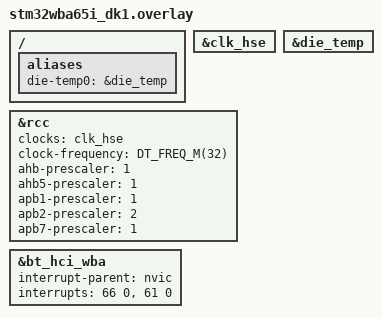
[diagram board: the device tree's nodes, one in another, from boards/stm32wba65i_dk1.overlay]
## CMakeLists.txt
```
# SPDX-License-Identifier: Apache-2.0
cmake_minimum_required(VERSION 3.20.0)

find_package(Zephyr REQUIRED HINTS $ENV{ZEPHYR_BASE})
project(bleberry LANGUAGES C)

# --- Locate the Berry interpreter (fetched by west, see west.yml) ------------

if(NOT DEFINED WEST_TOPDIR)
  get_filename_component(WEST_TOPDIR ${ZEPHYR_BASE}/.. ABSOLUTE)
endif()

set(BERRY_DIR ${WEST_TOPDIR}/modules/lib/berry CACHE PATH
    "Path to the Berry language source tree")

if(NOT EXISTS ${BERRY_DIR}/src/berry.h)
  message(FATAL_ERROR
    "Berry sources not found at ${BERRY_DIR}. Run 'west update' first, "
    "or set BERRY_DIR to a Berry checkout.")
endif()

set(BERRY_CONF_DIR ${CMAKE_CURRENT_SOURCE_DIR}/berry_conf)
set(BERRY_GENERATE_DIR ${BERRY_DIR}/generate)

file(GLOB BERRY_SOURCES ${BERRY_DIR}/src/*.c)
file(GLOB BERRY_HEADERS ${BERRY_DIR}/src/*.h)

# --- Berry pre-build code generation ("coc") ----------------------------------
# Berry solidifies its built-in classes/modules into flash. The coc tool scans
# the sources (plus our app sources, so custom const objects work too) and
# emits the constant tables into ${BERRY_DIR}/generate, where the Berry
# sources expect to find them.

add_custom_command(
  OUTPUT ${BERRY_GENERATE_DIR}/be_const_strtab.h
  COMMAND ${CMAKE_COMMAND} -E make_directory ${BERRY_GENERATE_DIR}
  COMMAND ${PYTHON_EXECUTABLE} ${BERRY_DIR}/tools/coc/coc
          -o ${BERRY_GENERATE_DIR}
          ${BERRY_DIR}/src
          ${CMAKE_CURRENT_SOURCE_DIR}/src
          -c ${BERRY_CONF_DIR}/berry_conf.h
  DEPENDS ${BERRY_SOURCES} ${BERRY_HEADERS} ${BERRY_CONF_DIR}/berry_conf.h
  COMMENT "Berry: generating precompiled objects (coc)"
)
add_custom_target(berry_coc DEPENDS ${BERRY_GENERATE_DIR}/be_const_strtab.h)

# --- Firmware git hash (regenerated on every build) ---------------------------

set(BLEBERRY_GIT_H ${CMAKE_BINARY_DIR}/bleberry_git.h)
add_custom_target(bleberry_git_hash
  COMMAND ${CMAKE_COMMAND}
          -DSOURCE_DIR=${CMAKE_CURRENT_SOURCE_DIR}
          -DOUT=${BLEBERRY_GIT_H}
          -P ${CMAKE_CURRENT_SOURCE_DIR}/cmake/git_hash.cmake
  BYPRODUCTS ${BLEBERRY_GIT_H}
  COMMENT "Updating bleberry_git.h"
)

# --- Application ---------------------------------------------------------------
# The Berry core is compiled straight into the app target: zephyr_library()
# is not available to application CMakeLists (Zephyr application mode).

target_sources(app PRIVATE
  ${BERRY_SOURCES}
  src/main.c
  src/nus_io.c
  src/berry_repl.c
  src/berry_io.c
  src/bb_runtime.c
  src/berry_port.c
  src/be_modtab.c
)
target_include_directories(app PRIVATE
  src
  ${BERRY_DIR}/src
  ${BERRY_CONF_DIR}
  ${CMAKE_BINARY_DIR}
)
add_dependencies(app berry_coc bleberry_git_hash)
```

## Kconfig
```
# SPDX-License-Identifier: Apache-2.0

menu "BLEberry - Berry REPL over BLE NUS"

config BLEBERRY_ECHO
	bool "Echo received characters back over NUS"
	help
	  Enable this when the connected terminal does not display the
	  characters it sends (raw character terminals). Most mobile NUS
	  terminal apps (nRF Toolbox, Serial Bluetooth Terminal) show sent
	  lines themselves, so the default is off.

config BLEBERRY_LINE_MAX
	int "Maximum REPL input line length"
	default 256

config BLEBERRY_RX_RINGBUF_SIZE
	int "Receive ring buffer size in bytes"
	default 1024

config BLEBERRY_TX_BUF_SIZE
	int "Transmit coalescing buffer size in bytes"
	default 244

config BLEBERRY_REPL_STACK_SIZE
	int "Stack size of the Berry REPL thread"
	default 12288
	help
	  The Berry compiler uses recursive descent parsing, so the REPL
	  thread needs a generous stack.

config BLEBERRY_TICK_MS
	int "Scheduler tick for sps.every() tasks in ms"
	default 10
	help
	  While the REPL waits for input it periodically runs due
	  BlockBerry mini-PLC tasks (sps.every). This sets the polling
	  granularity; task intervals shorter than this are not useful.

endmenu

source "Kconfig.zephyr"
```

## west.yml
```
# BLEberry west manifest
#
# Workspace layout (T2 topology, this repo is the manifest repo):
#
#   <workspace>/
#   ├── bleberry/            <- this repository
#   ├── zephyr/              <- Zephyr RTOS (main)
#   └── modules/
#       ├── hal/stm32/       <- STM32 HAL + BLE link layer
#       └── lib/berry/       <- Berry scripting language
#
# Setup:
#   west init -l bleberry
#   west update
manifest:
  remotes:
    - name: zephyrproject-rtos
      url-base: https://github.com/zephyrproject-rtos
    - name: berry-lang
      url-base: https://github.com/berry-lang

  projects:
    - name: zephyr
      remote: zephyrproject-rtos
      revision: main
      import:
        # Only pull what the STM32WBA targets actually need.
        name-allowlist:
          - cmsis
          - cmsis_6
          - hal_stm32
          - mbedtls        # PSA crypto for the Bluetooth host
          - tf-psa-crypto  # PSA crypto core used by mbedtls 4.x

    - name: berry
      remote: berry-lang
      revision: master
      path: modules/lib/berry

  self:
    path: bleberry
```

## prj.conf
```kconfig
# Bluetooth LE peripheral with Nordic UART Service
CONFIG_BT=y
CONFIG_BT_PERIPHERAL=y
CONFIG_BT_ZEPHYR_NUS=y
CONFIG_BT_DEVICE_NAME="BLEberry"

# Larger ATT MTU / data length for a snappier REPL (peer must request it)
CONFIG_BT_L2CAP_TX_MTU=247
CONFIG_BT_BUF_ACL_TX_SIZE=251
CONFIG_BT_BUF_ACL_RX_SIZE=251

# Berry heap: the interpreter allocates from the libc malloc arena.
# Boards with more SRAM raise this in boards/<board>.conf.
CONFIG_COMMON_LIBC_MALLOC_ARENA_SIZE=32768

# Berry prints reals via printf-family formatting
CONFIG_PICOLIBC_IO_FLOAT=y

# led() native function
CONFIG_GPIO=y

# reboot() native function
CONFIG_REBOOT=y

CONFIG_RING_BUFFER=y

# Keep the UART console for log output; the REPL itself runs over BLE
CONFIG_LOG=y
CONFIG_LOG_DEFAULT_LEVEL=3
```

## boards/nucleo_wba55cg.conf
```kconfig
# STM32WBA55CG: 128 KiB SRAM - keep a moderate Berry heap
CONFIG_COMMON_LIBC_MALLOC_ARENA_SIZE=49152

# temp(): die temperature sensor (via ADC4)
CONFIG_ADC=y
CONFIG_SENSOR=y
```

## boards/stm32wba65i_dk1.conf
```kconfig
# STM32WBA65RI: 512 KiB SRAM - plenty of room for the Berry heap
CONFIG_COMMON_LIBC_MALLOC_ARENA_SIZE=196608

# temp(): die temperature sensor (via ADC4)
CONFIG_SENSOR=y

# joy(): 5-way joystick on ADC4 channel 6 (adc-keys, input subsystem)
CONFIG_INPUT=y
```

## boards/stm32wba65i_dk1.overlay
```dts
/*
 * STM32WBA65I-DK1 on Zephyr 4.4.2: radio clock, die-temp (RF calib), IRQs.
 *
 * Board DTS defaults to HSE/2 @ 16 MHz and ahb5/2 — too slow for the BLE
 * link layer (HCI comes up, advertising is not on air). Align with upstream /
 * nucleo_wba65ri: 32 MHz SYSCLK, ahb5-prescaler = 1.
 */

/ {
	aliases {
		die-temp0 = &die_temp;
	};
};

&clk_hse {
	status = "okay";
	/delete-property/ hse-div2;
	/delete-property/ hse-trimming;
};

&rcc {
	clocks = <&clk_hse>;
	clock-frequency = <DT_FREQ_M(32)>; /* minimum for radio events */
	ahb-prescaler = <1>;
	ahb5-prescaler = <1>;
	apb1-prescaler = <1>;
	apb2-prescaler = <2>;
	apb7-prescaler = <1>;
};

&die_temp {
	status = "okay";
};

/*
 * Radio IRQ (66) + SW-low (HASH=61) so NUM_IRQS is large enough
 * (Zephyr 4.4 does not yet declare these on WBA65).
 */
&bt_hci_wba {
	interrupt-parent = <&nvic>;
	interrupts = <66 0>, <61 0>;
	interrupt-names = "radio", "radio-sw-low";
};
```

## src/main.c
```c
/* SPDX-License-Identifier: Apache-2.0
 *
 * BLEberry: Berry language REPL over the Bluetooth Nordic UART Service.
 *
 * Advertises as a connectable peripheral with the NUS UUID; once a
 * central subscribes to the TX characteristic, the Berry REPL banner
 * and prompt are sent and the terminal is live.
 */
#include <zephyr/kernel.h>
#include <zephyr/bluetooth/bluetooth.h>
#include <zephyr/bluetooth/conn.h>
#include <zephyr/bluetooth/services/nus.h>
#include <zephyr/logging/log.h>

#include "nus_io.h"

LOG_MODULE_REGISTER(bleberry, CONFIG_LOG_DEFAULT_LEVEL);

const char *bleberry_banner(void);

#define DEVICE_NAME	CONFIG_BT_DEVICE_NAME
#define DEVICE_NAME_LEN	(sizeof(DEVICE_NAME) - 1)

static const struct bt_data ad[] = {
	BT_DATA_BYTES(BT_DATA_FLAGS, (BT_LE_AD_GENERAL | BT_LE_AD_NO_BREDR)),
	BT_DATA(BT_DATA_NAME_COMPLETE, DEVICE_NAME, DEVICE_NAME_LEN),
};

static const struct bt_data sd[] = {
	BT_DATA_BYTES(BT_DATA_UUID128_ALL, BT_UUID_NUS_SRV_VAL),
};

static void adv_restart(struct k_work *work)
{
	ARG_UNUSED(work);

	int err = bt_le_adv_start(BT_LE_ADV_CONN_FAST_1,
				  ad, ARRAY_SIZE(ad), sd, ARRAY_SIZE(sd));
	if (err && err != -EALREADY) {
		LOG_ERR("Advertising restart failed (err %d)", err);
	}
}
static K_WORK_DEFINE(adv_work, adv_restart);

static void send_banner(struct k_work *work)
{
	ARG_UNUSED(work);

	nus_io_send_direct(bleberry_banner());
}
static K_WORK_DEFINE(banner_work, send_banner);

/* --- NUS callbacks ------------------------------------------------------ */

static void notif_enabled(bool enabled, void *ctx)
{
	ARG_UNUSED(ctx);

	nus_io_set_ready(enabled);
	LOG_INF("NUS notifications %s", enabled ? "enabled" : "disabled");

	if (enabled) {
		k_work_submit(&banner_work);
	}
}

static void received(struct bt_conn *conn, const void *data, uint16_t len,
		     void *ctx)
{
	ARG_UNUSED(conn);
	ARG_UNUSED(ctx);

	nus_io_rx_feed(data, len);
}

static struct bt_nus_cb nus_listener = {
	.notif_enabled = notif_enabled,
	.received = received,
};

/* --- connection callbacks ----------------------------------------------- */

static void connected(struct bt_conn *conn, uint8_t err)
{
	if (err) {
		LOG_ERR("Connection failed (err 0x%02x)", err);
		return;
	}
	nus_io_set_conn(conn);
	LOG_INF("Connected");
}

static void disconnected(struct bt_conn *conn, uint8_t reason)
{
	ARG_UNUSED(conn);

	nus_io_set_conn(NULL);
	nus_io_set_ready(false);
	LOG_INF("Disconnected (reason 0x%02x)", reason);
}

static void recycled(void)
{
	k_work_submit(&adv_work);
}

BT_CONN_CB_DEFINE(conn_callbacks) = {
	.connected = connected,
	.disconnected = disconnected,
	.recycled = recycled,
};

int main(void)
{
	int err;

	err = bt_nus_cb_register(&nus_listener, NULL);
	if (err) {
		LOG_ERR("Failed to register NUS callbacks (err %d)", err);
		return err;
	}

	err = bt_enable(NULL);
	if (err) {
		LOG_ERR("Failed to enable Bluetooth (err %d)", err);
		return err;
	}

	err = bt_le_adv_start(BT_LE_ADV_CONN_FAST_1,
			      ad, ARRAY_SIZE(ad), sd, ARRAY_SIZE(sd));
	if (err) {
		LOG_ERR("Failed to start advertising (err %d)", err);
		return err;
	}

	LOG_INF("BLEberry up, advertising as \"%s\"", DEVICE_NAME);
	return 0;
}
```

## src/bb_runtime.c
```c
/* SPDX-License-Identifier: Apache-2.0
 *
 * BlockBerry runtime: the Berry-side library that code generated by the
 * BlockBerry editor (blockberry-editor/src/berry_generator.ts) calls into:
 *
 *   sps.every(ms, fn), sps.wait(ms), sps.input(ch), sps.output(ch, v)
 *   sensor.ready(), sensor.temp()
 *   escalation.raise_if(id, cond, level, msg, cooldown)
 *   signal.set(name, state)
 *   monitor.record(metric, value, unit)
 *   log.print(msg)
 *
 * Channels are plain string parameters. Board specifics are resolved here:
 *   "LED0".."LED2"      user LEDs
 *   "SW0".."SW2"        user buttons (boards with gpio-keys)
 *   "JOY_UP" etc.       joystick (boards with adc-keys)
 *   "D0".."D15"         Arduino R3 header pins (board-specific map)
 *   "PA0".."PH15"       any GPIO by port/pin
 *
 * The cyclic tasks registered with sps.every() are driven by _bb_tick(),
 * which the REPL thread calls whenever it is idle waiting for input.
 */
#include <zephyr/kernel.h>
#include <zephyr/devicetree.h>
#include <zephyr/logging/log.h>

#include "berry.h"
#include "bb_runtime.h"

LOG_MODULE_REGISTER(bb_runtime, CONFIG_LOG_DEFAULT_LEVEL);

static const char bb_runtime_be[] =
	"import string\n"
	"_bb_tasks = []\n"
	"_bb_esc = {}\n"
	"_bb_sig = {}\n"
	"_bb_cfg = {}\n"
	"_bb_cur = nil\n"
	/* "PA5" -> ['a', 5] */
	"def _bb_pin(ch)\n"
	"  if size(ch) < 3 return nil end\n"
	"  var s = string.toupper(ch)\n"
	"  if s[0] != 'P' return nil end\n"
	"  var p = s[1]\n"
	"  if p < 'A' || p > 'H' return nil end\n"
	"  var pin = 0\n"
	"  var i = 2\n"
	"  while i < size(s)\n"
	"    var c = string.byte(s[i])\n"
	"    if c < 0x30 || c > 0x39 return nil end\n"
	"    pin = pin * 10 + (c - 0x30)\n"
	"    i += 1\n"
	"  end\n"
	"  if pin > 15 return nil end\n"
	"  return [string.tolower(p), pin]\n"
	"end\n"
	/* Arduino R3 header map (board-specific) */
	"_bb_dmap = {"
#if defined(CONFIG_BOARD_STM32WBA65I_DK1)
	"'D0':['a',11],'D1':['a',12],'D2':['e',0],'D3':['b',13],"
	"'D4':['a',3],'D5':['b',14],'D6':['b',0],'D7':['d',14],"
	"'D8':['a',10],'D9':['b',11],'D10':['b',9],'D11':['c',3],"
	"'D12':['a',9],'D13':['b',10],'D14':['b',1],'D15':['b',2]"
#endif
	"}\n"
	"def _bb_gpio(ch)\n"
	"  var pp = _bb_dmap.find(string.toupper(ch))\n"
	"  if pp == nil pp = _bb_pin(ch) end\n"
	"  return pp\n"
	"end\n"
	/* digital input by channel name */
	"def _bb_din(ch)\n"
	"  ch = str(ch)\n"
#ifdef CONFIG_INPUT
	"  if ch == 'JOY_UP' return joy() == 'up' end\n"
	"  if ch == 'JOY_DOWN' return joy() == 'down' end\n"
	"  if ch == 'JOY_LEFT' return joy() == 'left' end\n"
	"  if ch == 'JOY_RIGHT' return joy() == 'right' end\n"
	"  if ch == 'JOY_SELECT' return joy() == 'enter' end\n"
#endif
#if DT_NODE_EXISTS(DT_ALIAS(sw0))
	"  if ch == 'SW0' return button(0) != 0 end\n"
#endif
#if DT_NODE_EXISTS(DT_ALIAS(sw1))
	"  if ch == 'SW1' return button(1) != 0 end\n"
#endif
#if DT_NODE_EXISTS(DT_ALIAS(sw2))
	"  if ch == 'SW2' return button(2) != 0 end\n"
#endif
	"  var pp = _bb_gpio(ch)\n"
	"  if pp == nil raise 'value_error', 'unknown input channel: ' + ch end\n"
	"  if _bb_cfg.find(ch) == nil\n"
	"    pinmode(pp[0], pp[1], 'in_pu')\n"
	"    _bb_cfg[ch] = true\n"
	"  end\n"
	"  return dread(pp[0], pp[1]) != 0\n"
	"end\n"
	/* digital output by channel name */
	"def _bb_dout(ch, v)\n"
	"  ch = str(ch)\n"
	"  v = bool(v)\n"
#if DT_NODE_EXISTS(DT_ALIAS(led0))
	"  if ch == 'LED0' led(0, v) return end\n"
#endif
#if DT_NODE_EXISTS(DT_ALIAS(led1))
	"  if ch == 'LED1' led(1, v) return end\n"
#endif
#if DT_NODE_EXISTS(DT_ALIAS(led2))
	"  if ch == 'LED2' led(2, v) return end\n"
#endif
	"  var pp = _bb_gpio(ch)\n"
	"  if pp == nil raise 'value_error', 'unknown output channel: ' + ch end\n"
	"  if _bb_cfg.find(ch) == nil\n"
	"    pinmode(pp[0], pp[1], 'out')\n"
	"    _bb_cfg[ch] = true\n"
	"  end\n"
	"  dwrite(pp[0], pp[1], v)\n"
	"end\n"
	/* --- log --- */
	"log = module('log')\n"
	"log.print = def (msg) print('[log] ' + str(msg)) end\n"
	/* --- sps: cyclic mini PLC --- */
	"sps = module('sps')\n"
	"sps.every = def (interval, fn)\n"
	"  _bb_tasks.push({'i': int(interval), 'fn': fn, 'next': millis(), 'sleep': millis()})\n"
	"end\n"
	"sps.wait = def (ms)\n"
	"  if _bb_cur != nil\n"
	"    _bb_cur['sleep'] = millis() + int(ms)\n"
	"    raise 'bb_wait'\n"
	"  end\n"
	"end\n"
	"sps.input = def (ch) return _bb_din(ch) end\n"
	"sps.output = def (ch, v) _bb_dout(ch, v) end\n"
	"sps.clear = def () _bb_tasks = [] end\n"
	"def _bb_tick()\n"
	"  var now = millis()\n"
	"  for t: _bb_tasks\n"
	"    if now - t['next'] >= 0 && now - t['sleep'] >= 0\n"
	"      t['next'] = now + t['i']\n"
	"      _bb_cur = t\n"
	"      try\n"
	"        t['fn']()\n"
	"      except 'bb_wait'\n"
	"      except .. as e, m\n"
	"        log.print('task error: ' + str(e) + ': ' + str(m))\n"
	"      end\n"
	"      _bb_cur = nil\n"
	"    end\n"
	"  end\n"
	"end\n"
	/* --- sensor: die temperature --- */
	"sensor = module('sensor')\n"
#if defined(CONFIG_SENSOR) && DT_NODE_EXISTS(DT_ALIAS(die_temp0))
	"sensor.ready = def ()\n"
	"  try\n"
	"    temp()\n"
	"    return true\n"
	"  except ..\n"
	"    return false\n"
	"  end\n"
	"end\n"
	"sensor.temp = def () return temp() end\n"
#else
	"sensor.ready = def () return false end\n"
	"sensor.temp = def () raise 'io_error', 'no temperature sensor' end\n"
#endif
	/* --- signal: named states mapped to the user LEDs --- */
	"signal = module('signal')\n"
	"signal.set = def (name, state)\n"
	"  _bb_sig[str(name)] = str(state)\n"
	"  var g = state == 'normal'\n"
	"  var r = state == 'warning' || state == 'alarm'\n"
#if DT_NODE_EXISTS(DT_ALIAS(led0))
	"  led(0, g)\n"
#endif
#if DT_NODE_EXISTS(DT_ALIAS(led1))
	"  led(1, r)\n"
#endif
	"  if !g && !r && state != 'off'\n"
	"    log.print('signal ' + str(name) + ' -> ' + str(state))\n"
	"  end\n"
	"end\n"
	"signal.get = def (name) return _bb_sig.find(str(name)) end\n"
	/* --- monitor: measurement log --- */
	"monitor = module('monitor')\n"
	"monitor.record = def (metric, value, unit)\n"
	"  log.print(str(metric) + ' = ' + str(value) + ' ' + str(unit))\n"
	"end\n"
	/* --- escalation: stateful alarms with cooldown --- */
	"escalation = module('escalation')\n"
	"escalation.raise_if = def (id, cond, level, msg, cooldown)\n"
	"  var e = _bb_esc.find(id)\n"
	"  if e == nil\n"
	"    e = {'active': false, 'last': nil}\n"
	"    _bb_esc[id] = e\n"
	"  end\n"
	"  if !cond\n"
	"    e['active'] = false\n"
	"    return false\n"
	"  end\n"
	"  if e['active'] return false end\n"
	"  var now = millis()\n"
	"  if e['last'] != nil && now - e['last'] < int(cooldown) * 1000\n"
	"    return false\n"
	"  end\n"
	"  e['active'] = true\n"
	"  e['last'] = now\n"
	"  log.print('[' + str(level) + '] ' + str(msg))\n"
	"  return true\n"
	"end\n";

int bb_runtime_load(bvm *vm)
{
	if (be_loadbuffer(vm, "bb_runtime", bb_runtime_be,
			  sizeof(bb_runtime_be) - 1) != 0) {
		LOG_ERR("BlockBerry runtime failed to compile");
		be_dumpexcept(vm);
		return -EINVAL;
	}
	if (be_pcall(vm, 0) != 0) {
		LOG_ERR("BlockBerry runtime failed to run");
		be_dumpexcept(vm);
		be_pop(vm, 1);
		return -EINVAL;
	}
	be_pop(vm, 1);
	return 0;
}

void bb_runtime_tick(bvm *vm)
{
	static bool in_tick;

	if (vm == NULL || in_tick) {
		return;
	}
	in_tick = true;

	be_getglobal(vm, "_bb_tick");
	if (be_isfunction(vm, -1)) {
		if (be_pcall(vm, 0) != 0) {
			be_dumpexcept(vm);
		}
	}
	be_pop(vm, 1);

	in_tick = false;
}
```

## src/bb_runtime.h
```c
/* SPDX-License-Identifier: Apache-2.0 */
#ifndef BLEBERRY_BB_RUNTIME_H_
#define BLEBERRY_BB_RUNTIME_H_

#include "berry.h"

/* Load the BlockBerry runtime (sps/sensor/escalation/signal/monitor/log)
 * into the VM. Returns 0 on success. */
int bb_runtime_load(bvm *vm);

/* Run due sps.every() tasks. Called from the REPL thread while it is
 * idle waiting for input. Safe to call with NULL. */
void bb_runtime_tick(bvm *vm);

#endif /* BLEBERRY_BB_RUNTIME_H_ */
```

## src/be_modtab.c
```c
/********************************************************************
** Berry module table for BLEberry.
**
** Adapted from berry/default/be_modtab.c (see the Berry LICENSE).
** Only the modules enabled in berry_conf.h end up in the table.
********************************************************************/
#include "berry.h"

be_extern_native_module(string);
be_extern_native_module(json);
be_extern_native_module(math);
be_extern_native_module(time);
be_extern_native_module(os);
be_extern_native_module(global);
be_extern_native_module(sys);
be_extern_native_module(debug);
be_extern_native_module(gc);
be_extern_native_module(solidify);
be_extern_native_module(introspect);
be_extern_native_module(strict);
be_extern_native_module(undefined);

BERRY_LOCAL const bntvmodule_t* const be_module_table[] = {
#if BE_USE_STRING_MODULE
    &be_native_module(string),
#endif
#if BE_USE_JSON_MODULE
    &be_native_module(json),
#endif
#if BE_USE_MATH_MODULE
    &be_native_module(math),
#endif
#if BE_USE_TIME_MODULE
    &be_native_module(time),
#endif
#if BE_USE_OS_MODULE
    &be_native_module(os),
#endif
#if BE_USE_GLOBAL_MODULE
    &be_native_module(global),
#endif
#if BE_USE_SYS_MODULE
    &be_native_module(sys),
#endif
#if BE_USE_DEBUG_MODULE
    &be_native_module(debug),
#endif
#if BE_USE_GC_MODULE
    &be_native_module(gc),
#endif
#if BE_USE_SOLIDIFY_MODULE
    &be_native_module(solidify),
#endif
#if BE_USE_INTROSPECT_MODULE
    &be_native_module(introspect),
#endif
#if BE_USE_STRICT_MODULE
    &be_native_module(strict),
#endif
    &be_native_module(undefined),
    NULL /* do not remove */
};

BERRY_LOCAL bclass_array be_class_table = {
    NULL, /* do not remove */
};
```

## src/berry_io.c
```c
/* SPDX-License-Identifier: Apache-2.0
 *
 * Native Berry functions for board I/O:
 *
 *   millis()               uptime in milliseconds
 *   reboot()               cold reboot
 *   led(on) / led(i, on)   user LEDs (led0..led2 aliases)
 *   button([i])            user buttons (sw0..sw2 aliases), 1 = pressed
 *   joy()                  joystick direction (adc-keys, input subsystem)
 *   temp()                 die temperature in degrees Celsius
 *   pinmode(p, pin, mode)  configure any GPIO, p = "a".."h"
 *   dwrite(p, pin, v)      write GPIO
 *   dread(p, pin)          read GPIO
 *   help()                 list what is available on this board
 *
 * Everything is guarded by devicetree/Kconfig, so boards without a
 * given peripheral simply don't get the corresponding function.
 */
#include <zephyr/kernel.h>
#include <zephyr/device.h>
#include <zephyr/devicetree.h>
#include <zephyr/drivers/gpio.h>
#include <zephyr/sys/reboot.h>
#include <ctype.h>
#include <stdio.h>

#include "berry_io.h"
#include "nus_io.h"
#include "bleberry_git.h"

#if defined(CONFIG_SENSOR) && DT_NODE_EXISTS(DT_ALIAS(die_temp0))
#define HAS_DIE_TEMP 1
#include <zephyr/drivers/sensor.h>
#endif

#if defined(CONFIG_INPUT)
#define HAS_JOYSTICK 1
#include <zephyr/input/input.h>
#include <zephyr/dt-bindings/input/input-event-codes.h>
#endif

/* --- user LEDs (aliases led0..led2) ------------------------------------- */

static const struct gpio_dt_spec leds[] = {
#if DT_NODE_EXISTS(DT_ALIAS(led0))
	GPIO_DT_SPEC_GET(DT_ALIAS(led0), gpios),
#endif
#if DT_NODE_EXISTS(DT_ALIAS(led1))
	GPIO_DT_SPEC_GET(DT_ALIAS(led1), gpios),
#endif
#if DT_NODE_EXISTS(DT_ALIAS(led2))
	GPIO_DT_SPEC_GET(DT_ALIAS(led2), gpios),
#endif
};

/* --- user buttons (aliases sw0..sw2) ------------------------------------- */

static const struct gpio_dt_spec buttons[] = {
#if DT_NODE_EXISTS(DT_ALIAS(sw0))
	GPIO_DT_SPEC_GET(DT_ALIAS(sw0), gpios),
#endif
#if DT_NODE_EXISTS(DT_ALIAS(sw1))
	GPIO_DT_SPEC_GET(DT_ALIAS(sw1), gpios),
#endif
#if DT_NODE_EXISTS(DT_ALIAS(sw2))
	GPIO_DT_SPEC_GET(DT_ALIAS(sw2), gpios),
#endif
};

/* --- raw GPIO port access ------------------------------------------------ */

static const struct {
	char name;
	const struct device *dev;
} gpio_ports[] = {
#if DT_NODE_HAS_STATUS_OKAY(DT_NODELABEL(gpioa))
	{ 'a', DEVICE_DT_GET(DT_NODELABEL(gpioa)) },
#endif
#if DT_NODE_HAS_STATUS_OKAY(DT_NODELABEL(gpiob))
	{ 'b', DEVICE_DT_GET(DT_NODELABEL(gpiob)) },
#endif
#if DT_NODE_HAS_STATUS_OKAY(DT_NODELABEL(gpioc))
	{ 'c', DEVICE_DT_GET(DT_NODELABEL(gpioc)) },
#endif
#if DT_NODE_HAS_STATUS_OKAY(DT_NODELABEL(gpiod))
	{ 'd', DEVICE_DT_GET(DT_NODELABEL(gpiod)) },
#endif
#if DT_NODE_HAS_STATUS_OKAY(DT_NODELABEL(gpioe))
	{ 'e', DEVICE_DT_GET(DT_NODELABEL(gpioe)) },
#endif
#if DT_NODE_HAS_STATUS_OKAY(DT_NODELABEL(gpiof))
	{ 'f', DEVICE_DT_GET(DT_NODELABEL(gpiof)) },
#endif
#if DT_NODE_HAS_STATUS_OKAY(DT_NODELABEL(gpiog))
	{ 'g', DEVICE_DT_GET(DT_NODELABEL(gpiog)) },
#endif
#if DT_NODE_HAS_STATUS_OKAY(DT_NODELABEL(gpioh))
	{ 'h', DEVICE_DT_GET(DT_NODELABEL(gpioh)) },
#endif
};

/* Resolve a port argument ("a", "A", "pa", 0) to a GPIO device. */
static const struct device *port_arg(bvm *vm, int index)
{
	char name = 0;

	if (be_isint(vm, index)) {
		bint n = be_toint(vm, index);

		if (n >= 0 && n < 26) {
			name = (char)('a' + n);
		}
	} else if (be_isstring(vm, index)) {
		const char *s = be_tostring(vm, index);

		if (s[0] == 'p' || s[0] == 'P') {
			s++;
		}
		name = (char)tolower((unsigned char)s[0]);
	}

	for (size_t i = 0; i < ARRAY_SIZE(gpio_ports); i++) {
		if (gpio_ports[i].name == name) {
			return gpio_ports[i].dev;
		}
	}
	be_raise(vm, "value_error", "unknown GPIO port");
	return NULL;
}

static gpio_pin_t pin_arg(bvm *vm, int index)
{
	if (!be_isint(vm, index)) {
		be_raise(vm, "type_error", "pin must be an integer");
	}

	bint pin = be_toint(vm, index);

	if (pin < 0 || pin > 15) {
		be_raise(vm, "value_error", "pin must be 0..15");
	}
	return (gpio_pin_t)pin;
}

static bool bool_arg(bvm *vm, int index)
{
	if (be_isbool(vm, index)) {
		return be_tobool(vm, index);
	}
	if (be_isint(vm, index)) {
		return be_toint(vm, index) != 0;
	}
	be_raise(vm, "type_error", "expected bool or int");
	return false;
}

/* --- native functions ----------------------------------------------------- */

static int m_millis(bvm *vm)
{
	be_pushint(vm, (bint)k_uptime_get_32());
	be_return(vm);
}

static int m_reboot(bvm *vm)
{
	(void)vm;
	nus_io_flush();
	k_sleep(K_MSEC(100));
	sys_reboot(SYS_REBOOT_COLD);
	be_return_nil(vm);
}

#if DT_NODE_EXISTS(DT_ALIAS(led0))
static int m_led(bvm *vm)
{
	int argc = be_top(vm);
	int idx = 0;
	int argi = 1;

	if (argc >= 2) {
		if (!be_isint(vm, 1)) {
			be_raise(vm, "type_error", "led index must be an integer");
		}
		idx = (int)be_toint(vm, 1);
		argi = 2;
	}
	if (argc < argi) {
		be_raise(vm, "value_error", "usage: led(on) or led(i, on)");
	}
	if (idx < 0 || idx >= (int)ARRAY_SIZE(leds)) {
		be_raise(vm, "index_error", "no such LED");
	}
	gpio_pin_set_dt(&leds[idx], bool_arg(vm, argi));
	be_return_nil(vm);
}
#endif

#if DT_NODE_EXISTS(DT_ALIAS(sw0))
static int m_button(bvm *vm)
{
	int idx = 0;

	if (be_top(vm) >= 1 && be_isint(vm, 1)) {
		idx = (int)be_toint(vm, 1);
	}
	if (idx < 0 || idx >= (int)ARRAY_SIZE(buttons)) {
		be_raise(vm, "index_error", "no such button");
	}
	be_pushint(vm, gpio_pin_get_dt(&buttons[idx]) > 0 ? 1 : 0);
	be_return(vm);
}
#endif

#ifdef HAS_JOYSTICK
static atomic_t joy_code = ATOMIC_INIT(0);

static void joy_input_cb(struct input_event *evt, void *user_data)
{
	ARG_UNUSED(user_data);

	if (evt->type != INPUT_EV_KEY) {
		return;
	}
	if (evt->value) {
		atomic_set(&joy_code, evt->code);
	} else if (atomic_get(&joy_code) == evt->code) {
		atomic_set(&joy_code, 0);
	}
}
INPUT_CALLBACK_DEFINE(NULL, joy_input_cb, NULL);

static int m_joy(bvm *vm)
{
	const char *s;

	switch (atomic_get(&joy_code)) {
	case INPUT_KEY_UP:    s = "up";    break;
	case INPUT_KEY_DOWN:  s = "down";  break;
	case INPUT_KEY_LEFT:  s = "left";  break;
	case INPUT_KEY_RIGHT: s = "right"; break;
	case INPUT_KEY_ENTER: s = "enter"; break;
	default:              s = "";      break;
	}
	be_pushstring(vm, s);
	be_return(vm);
}
#endif /* HAS_JOYSTICK */

#ifdef HAS_DIE_TEMP
static const struct device *const die_temp_dev = DEVICE_DT_GET(DT_ALIAS(die_temp0));

static int m_temp(bvm *vm)
{
	struct sensor_value val;

	if (!device_is_ready(die_temp_dev) ||
	    sensor_sample_fetch(die_temp_dev) != 0 ||
	    sensor_channel_get(die_temp_dev, SENSOR_CHAN_DIE_TEMP, &val) != 0) {
		be_raise(vm, "io_error", "die temperature sensor failed");
	}
	be_pushreal(vm, (breal)sensor_value_to_double(&val));
	be_return(vm);
}
#endif /* HAS_DIE_TEMP */

static int m_pinmode(bvm *vm)
{
	const struct device *dev = port_arg(vm, 1);
	gpio_pin_t pin = pin_arg(vm, 2);
	gpio_flags_t flags;

	if (be_top(vm) < 3 || !be_isstring(vm, 3)) {
		be_raise(vm, "type_error",
			 "mode must be \"in\", \"in_pu\", \"in_pd\", \"out\" or \"out_od\"");
	}

	const char *mode = be_tostring(vm, 3);

	if (strcmp(mode, "in") == 0) {
		flags = GPIO_INPUT;
	} else if (strcmp(mode, "in_pu") == 0) {
		flags = GPIO_INPUT | GPIO_PULL_UP;
	} else if (strcmp(mode, "in_pd") == 0) {
		flags = GPIO_INPUT | GPIO_PULL_DOWN;
	} else if (strcmp(mode, "out") == 0) {
		flags = GPIO_OUTPUT_INACTIVE;
	} else if (strcmp(mode, "out_od") == 0) {
		flags = GPIO_OUTPUT_INACTIVE | GPIO_OPEN_DRAIN;
	} else {
		be_raise(vm, "value_error", "unknown GPIO mode");
		be_return_nil(vm);
	}

	if (gpio_pin_configure(dev, pin, flags) != 0) {
		be_raise(vm, "io_error", "gpio configure failed");
	}
	be_return_nil(vm);
}

static int m_dwrite(bvm *vm)
{
	const struct device *dev = port_arg(vm, 1);
	gpio_pin_t pin = pin_arg(vm, 2);

	if (be_top(vm) < 3) {
		be_raise(vm, "value_error", "usage: dwrite(port, pin, value)");
	}
	if (gpio_pin_set_raw(dev, pin, bool_arg(vm, 3) ? 1 : 0) != 0) {
		be_raise(vm, "io_error", "gpio write failed");
	}
	be_return_nil(vm);
}

static int m_dread(bvm *vm)
{
	const struct device *dev = port_arg(vm, 1);
	gpio_pin_t pin = pin_arg(vm, 2);
	int val = gpio_pin_get_raw(dev, pin);

	if (val < 0) {
		be_raise(vm, "io_error", "gpio read failed");
	}
	be_pushint(vm, val);
	be_return(vm);
}

static int m_help(bvm *vm)
{
	be_writestring("BLEberry REPL (" CONFIG_BOARD ", git " BLEBERRY_GIT_HASH ")"
		       " - built-in functions:\n"
		       "  help()                 this help\n"
		       "  millis()               uptime in ms\n"
		       "  reboot()               cold reboot\n");
#if DT_NODE_EXISTS(DT_ALIAS(led0))
	char led_line[64];

	snprintf(led_line, sizeof(led_line),
		 "  led(on), led(i, on)    user LEDs, i = 0..%d\n",
		 (int)ARRAY_SIZE(leds) - 1);
	be_writestring(led_line);
#endif
#if DT_NODE_EXISTS(DT_ALIAS(sw0))
	be_writestring("  button([i])            user button, 1 = pressed\n");
#endif
#ifdef HAS_JOYSTICK
	be_writestring("  joy()                  \"up\",\"down\",\"left\",\"right\",\"enter\" or \"\"\n");
#endif
#ifdef HAS_DIE_TEMP
	be_writestring("  temp()                 die temperature in deg C\n");
#endif
	be_writestring("  pinmode(p, pin, mode)  p=\"a\"..\"h\", mode: in,in_pu,in_pd,out,out_od\n"
		       "  dwrite(p, pin, v)      write GPIO pin\n"
		       "  dread(p, pin)          read GPIO pin\n"
		       "BlockBerry runtime: sps.every/wait/input/output, sensor.ready/temp,\n"
		       "  escalation.raise_if, signal.set, monitor.record, log.print\n"
		       "  channels: \"LED0\", \"SW0\", \"JOY_UP\", \"D2\"..\"D15\", \"PA0\"..\"PH15\"\n"
		       "modules: import string / math / json / gc / introspect\n"
		       "docs: https://berry-lang.github.io/\n");
	be_return_nil(vm);
}

/* --- init & registration -------------------------------------------------- */

void berry_io_init(void)
{
	for (size_t i = 0; i < ARRAY_SIZE(leds); i++) {
		if (gpio_is_ready_dt(&leds[i])) {
			gpio_pin_configure_dt(&leds[i], GPIO_OUTPUT_INACTIVE);
		}
	}
	for (size_t i = 0; i < ARRAY_SIZE(buttons); i++) {
		if (gpio_is_ready_dt(&buttons[i])) {
			gpio_pin_configure_dt(&buttons[i], GPIO_INPUT);
		}
	}
}

void berry_io_register(bvm *vm)
{
	be_regfunc(vm, "help", m_help);
	be_regfunc(vm, "millis", m_millis);
	be_regfunc(vm, "reboot", m_reboot);
#if DT_NODE_EXISTS(DT_ALIAS(led0))
	be_regfunc(vm, "led", m_led);
#endif
#if DT_NODE_EXISTS(DT_ALIAS(sw0))
	be_regfunc(vm, "button", m_button);
#endif
#ifdef HAS_JOYSTICK
	be_regfunc(vm, "joy", m_joy);
#endif
#ifdef HAS_DIE_TEMP
	be_regfunc(vm, "temp", m_temp);
#endif
	be_regfunc(vm, "pinmode", m_pinmode);
	be_regfunc(vm, "dwrite", m_dwrite);
	be_regfunc(vm, "dread", m_dread);
}
```

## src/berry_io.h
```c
/* SPDX-License-Identifier: Apache-2.0 */
#ifndef BLEBERRY_BERRY_IO_H_
#define BLEBERRY_BERRY_IO_H_

#include "berry.h"

/* Configure the board I/O (LEDs, buttons) once at startup. */
void berry_io_init(void);

/* Register all native functions (I/O, timing, help) with the VM. */
void berry_io_register(bvm *vm);

#endif /* BLEBERRY_BERRY_IO_H_ */
```

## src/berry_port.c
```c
/* SPDX-License-Identifier: Apache-2.0
 *
 * Berry OS port layer: standard output and input are routed to the
 * BLE NUS terminal, mirrored to the Zephyr console for debugging.
 *
 * With BE_USE_FILE_SYSTEM=0 and the os/sys/time modules disabled,
 * these two functions are the whole port surface Berry requires.
 */
#include <zephyr/kernel.h>
#include <zephyr/sys/printk.h>

#include "berry.h"
#include "nus_io.h"

BERRY_API void be_writebuffer(const char *buffer, size_t length)
{
	printk("%.*s", (int)length, buffer);
	nus_io_write(buffer, length);
}

BERRY_API char *be_readstring(char *buffer, size_t size)
{
	/* fgets-like semantics for Berry's input(): return the line
	 * with a trailing newline appended. */
	nus_io_flush();
	nus_io_read_line(buffer, size - 1);

	size_t len = strlen(buffer);

	buffer[len] = '\n';
	buffer[len + 1] = '\0';
	return buffer;
}

/* Some Berry core files (be_filelib.c, be_exec.c) reference the file
 * API even with BE_USE_FILE_SYSTEM=0. There is no file system on this
 * target, so open() fails cleanly at runtime. */

void *be_fopen(const char *filename, const char *modes)
{
	ARG_UNUSED(filename);
	ARG_UNUSED(modes);
	return NULL;
}

int be_fclose(void *hfile)
{
	ARG_UNUSED(hfile);
	return -1;
}

size_t be_fwrite(void *hfile, const void *buffer, size_t length)
{
	ARG_UNUSED(hfile);
	ARG_UNUSED(buffer);
	ARG_UNUSED(length);
	return 0;
}

size_t be_fread(void *hfile, void *buffer, size_t length)
{
	ARG_UNUSED(hfile);
	ARG_UNUSED(buffer);
	ARG_UNUSED(length);
	return 0;
}

char *be_fgets(void *hfile, void *buffer, int size)
{
	ARG_UNUSED(hfile);
	ARG_UNUSED(buffer);
	ARG_UNUSED(size);
	return NULL;
}

int be_fseek(void *hfile, long offset)
{
	ARG_UNUSED(hfile);
	ARG_UNUSED(offset);
	return -1;
}

long int be_ftell(void *hfile)
{
	ARG_UNUSED(hfile);
	return -1;
}

long int be_fflush(void *hfile)
{
	ARG_UNUSED(hfile);
	return 0;
}

size_t be_fsize(void *hfile)
{
	ARG_UNUSED(hfile);
	return 0;
}
```

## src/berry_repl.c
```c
/* SPDX-License-Identifier: Apache-2.0
 *
 * Berry REPL thread: owns the Berry VM and runs be_repl() forever,
 * reading lines from and writing results to the BLE NUS terminal.
 */
#include <zephyr/kernel.h>
#include <zephyr/logging/log.h>

#include "berry.h"
#include "be_repl.h"
#include "berry_io.h"
#include "bb_runtime.h"
#include "nus_io.h"

LOG_MODULE_REGISTER(berry_repl, CONFIG_LOG_DEFAULT_LEVEL);

#define BANNER \
	"BLEberry - Berry " BERRY_VERSION " on Zephyr (" CONFIG_BOARD ")\n" \
	"type berry code (e.g. 1+2) or help()\n"

static char line_buf[CONFIG_BLEBERRY_LINE_MAX];
static bvm *repl_vm;

static void repl_idle_tick(void)
{
	bb_runtime_tick(repl_vm);
}

static char *repl_getline(const char *prompt)
{
	be_writestring(prompt);
	nus_io_flush();
	return nus_io_read_line(line_buf, sizeof(line_buf));
}

const char *bleberry_banner(void)
{
	return BANNER "> ";
}

static void repl_thread(void *p1, void *p2, void *p3)
{
	ARG_UNUSED(p1);
	ARG_UNUSED(p2);
	ARG_UNUSED(p3);

	berry_io_init();
	nus_io_set_idle_hook(repl_idle_tick);

	for (;;) {
		bvm *vm = be_vm_new();

		if (vm == NULL) {
			LOG_ERR("Berry VM allocation failed");
			k_sleep(K_SECONDS(5));
			continue;
		}
		berry_io_register(vm);
		bb_runtime_load(vm);
		repl_vm = vm;

		be_writestring(BANNER);

		int res = be_repl(vm, repl_getline, NULL);

		if (res == BE_MALLOC_FAIL) {
			be_writestring("!! out of memory, restarting VM\n");
		} else {
			be_writestring("REPL terminated, restarting VM\n");
		}
		repl_vm = NULL;
		nus_io_flush();
		be_vm_delete(vm);
	}
}

K_THREAD_DEFINE(bleberry_repl, CONFIG_BLEBERRY_REPL_STACK_SIZE,
		repl_thread, NULL, NULL, NULL,
		K_PRIO_PREEMPT(10), 0, 0);
```

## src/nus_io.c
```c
/* SPDX-License-Identifier: Apache-2.0
 *
 * Line-oriented terminal I/O over the Bluetooth Nordic UART Service.
 *
 * RX: bytes arrive from the NUS 'received' callback and are queued in a
 * ring buffer; the REPL thread blocks on a semaphore and assembles lines.
 * TX: output is coalesced into a small buffer and flushed on newline,
 * buffer-full or an explicit flush, then sent as GATT notifications in
 * MTU-sized chunks.
 */
#include <zephyr/kernel.h>
#include <zephyr/sys/ring_buffer.h>
#include <zephyr/bluetooth/conn.h>
#include <zephyr/bluetooth/gatt.h>
#include <zephyr/bluetooth/services/nus.h>
#include <zephyr/logging/log.h>

#include "nus_io.h"

LOG_MODULE_REGISTER(nus_io, CONFIG_LOG_DEFAULT_LEVEL);

RING_BUF_DECLARE(rx_rb, CONFIG_BLEBERRY_RX_RINGBUF_SIZE);
static K_SEM_DEFINE(rx_sem, 0, 1);

static struct bt_conn *cur_conn;
static atomic_t tx_ready;

static char tx_buf[CONFIG_BLEBERRY_TX_BUF_SIZE];
static size_t tx_len;

void nus_io_rx_feed(const void *data, uint16_t len)
{
	uint32_t written = ring_buf_put(&rx_rb, data, len);

	if (written < len) {
		LOG_WRN("RX overflow, dropped %u bytes", len - written);
	}
	k_sem_give(&rx_sem);
}

void nus_io_set_conn(struct bt_conn *conn)
{
	cur_conn = conn;
}

void nus_io_set_ready(bool ready)
{
	atomic_set(&tx_ready, ready ? 1 : 0);
}

bool nus_io_is_ready(void)
{
	return atomic_get(&tx_ready) == 1;
}

static uint16_t tx_chunk_size(void)
{
	struct bt_conn *conn = cur_conn;

	if (conn != NULL) {
		uint16_t mtu = bt_gatt_get_mtu(conn);

		if (mtu > 3) {
			return MIN(mtu - 3, CONFIG_BLEBERRY_TX_BUF_SIZE);
		}
	}
	return 20; /* default ATT MTU 23 - 3 */
}

static void send_chunked(const char *data, size_t len)
{
	if (!nus_io_is_ready()) {
		return;
	}

	while (len > 0) {
		uint16_t chunk = MIN(len, tx_chunk_size());
		int err = bt_nus_send(NULL, data, chunk);

		if (err == -EAGAIN || err == -ENOMEM) {
			/* controller TX buffers full: back off and retry */
			k_sleep(K_MSEC(5));
			continue;
		}
		if (err) {
			/* peer gone or stack error: drop the rest */
			return;
		}
		data += chunk;
		len -= chunk;
	}
}

void nus_io_flush(void)
{
	if (tx_len > 0) {
		send_chunked(tx_buf, tx_len);
		tx_len = 0;
	}
}

void nus_io_write(const char *buf, size_t len)
{
	bool has_nl = false;

	for (size_t i = 0; i < len; i++) {
		tx_buf[tx_len++] = buf[i];
		if (buf[i] == '\n') {
			has_nl = true;
		}
		if (tx_len == sizeof(tx_buf)) {
			send_chunked(tx_buf, tx_len);
			tx_len = 0;
			has_nl = false;
		}
	}
	if (has_nl) {
		nus_io_flush();
	}
}

void nus_io_send_direct(const char *str)
{
	send_chunked(str, strlen(str));
}

static void (*idle_hook)(void);

void nus_io_set_idle_hook(void (*hook)(void))
{
	idle_hook = hook;
}

static uint8_t rx_getchar(void)
{
	uint8_t c;

	while (ring_buf_get(&rx_rb, &c, 1) == 0) {
		if (k_sem_take(&rx_sem, K_MSEC(CONFIG_BLEBERRY_TICK_MS)) != 0 &&
		    idle_hook != NULL) {
			idle_hook();
		}
	}
	return c;
}

char *nus_io_read_line(char *buf, size_t size)
{
	size_t pos = 0;

	for (;;) {
		uint8_t c = rx_getchar();

		if (c == '\r' || c == '\n') {
			/* swallow the LF of a CRLF pair */
			if (c == '\r') {
				uint8_t peek;

				if (ring_buf_peek(&rx_rb, &peek, 1) == 1 &&
				    peek == '\n') {
					ring_buf_get(&rx_rb, &peek, 1);
				}
			}
			if (IS_ENABLED(CONFIG_BLEBERRY_ECHO)) {
				nus_io_write("\r\n", 2);
				nus_io_flush();
			}
			buf[pos] = '\0';
			return buf;
		}

		if (c == 0x08 || c == 0x7f) { /* backspace / DEL */
			if (pos > 0) {
				pos--;
				if (IS_ENABLED(CONFIG_BLEBERRY_ECHO)) {
					nus_io_write("\b \b", 3);
					nus_io_flush();
				}
			}
			continue;
		}

		if (c < 0x20) { /* other control characters */
			continue;
		}

		if (pos < size - 1) {
			buf[pos++] = c;
			if (IS_ENABLED(CONFIG_BLEBERRY_ECHO)) {
				nus_io_write((char *)&c, 1);
				nus_io_flush();
			}
		}
	}
}
```

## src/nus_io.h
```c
/* SPDX-License-Identifier: Apache-2.0
 *
 * Line-oriented terminal I/O over the Bluetooth Nordic UART Service.
 */
#ifndef BLEBERRY_NUS_IO_H_
#define BLEBERRY_NUS_IO_H_

#include <stddef.h>
#include <stdint.h>
#include <stdbool.h>

struct bt_conn;

/* Feed bytes received from the NUS RX characteristic (any context). */
void nus_io_rx_feed(const void *data, uint16_t len);

/* Track the peer connection (for MTU-sized chunking). */
void nus_io_set_conn(struct bt_conn *conn);

/* Notification subscription state of the TX characteristic. */
void nus_io_set_ready(bool ready);
bool nus_io_is_ready(void);

/* Buffered write; flushes on '\n' or when the buffer fills. */
void nus_io_write(const char *buf, size_t len);

/* Flush the coalescing buffer to the peer. */
void nus_io_flush(void);

/* Send a string immediately, bypassing the coalescing buffer.
 * Safe to call from callbacks/work queue context. */
void nus_io_send_direct(const char *str);

/* Blocking: read one line (without the trailing newline) into buf,
 * handling backspace and optional echo. Returns buf. */
char *nus_io_read_line(char *buf, size_t size);

/* Hook invoked periodically (every CONFIG_BLEBERRY_TICK_MS) while
 * nus_io_read_line() is waiting for input. Runs in the reader thread. */
void nus_io_set_idle_hook(void (*hook)(void));

#endif /* BLEBERRY_NUS_IO_H_ */
```
